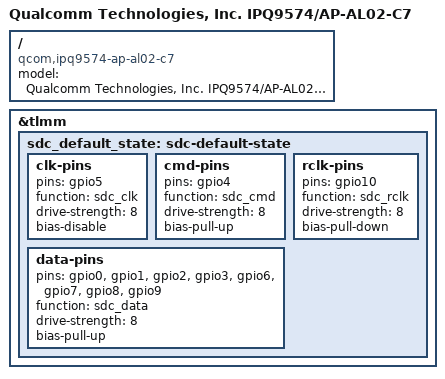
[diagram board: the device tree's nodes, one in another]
// SPDX-License-Identifier: (GPL-2.0+ OR BSD-3-Clause)
/*
 * IPQ9574 RDP433 board device tree source
 *
 * Copyright (c) 2020-2021 The Linux Foundation. All rights reserved.
 * Copyright (c) 2023 Qualcomm Innovation Center, Inc. All rights reserved.
 */

/dts-v1/;

#include "ipq9574-rdp-common.dtsi"

/ {
	model = "Qualcomm Technologies, Inc. IPQ9574/AP-AL02-C7";
	compatible = "qcom,ipq9574-ap-al02-c7", "qcom,ipq9574";
};

&tlmm {
	sdc_default_state: sdc-default-state {
		clk-pins {
			pins = "gpio5";
			function = "sdc_clk";
			drive-strength = <8>;
			bias-disable;
		};

		cmd-pins {
			pins = "gpio4";
			function = "sdc_cmd";
			drive-strength = <8>;
			bias-pull-up;
		};

		data-pins {
			pins = "gpio0", "gpio1", "gpio2",
			       "gpio3", "gpio6", "gpio7",
			       "gpio8", "gpio9";
			function = "sdc_data";
			drive-strength = <8>;
			bias-pull-up;
		};

		rclk-pins {
			pins = "gpio10";
			function = "sdc_rclk";
			drive-strength = <8>;
			bias-pull-down;
		};
	};
};
